# RTS591x register map
Vendor: Realtek Semiconductor Corp.; Series: RTS591x Series; File version: 1.0
CPU: ARMV8MML r0p0, little endian, MPU, FPU, VTOR, 3 interrupt priority bits, 4 SAU regions
Registers are 32-bit, read-write, reset 0x0 unless marked. A register's access mark holds for its fields unless they carry their own. Offsets are from the block's base; [hi:lo] are bit positions; {n}, {i} and the like mark numbered series; 'fields as' and 'values as' point back to an identical list.

## PUF — PUF Controller
Base 0x40010800
{0x0+4i} OTP[{i}] (i=0..255) — OTP BLOCK
{0x400+4i} PUF[{i}] (i=0..63) — PUF BLOCK
0x530 PUFZEROIZED — PUF ZEROIZATION REGISTER
{0x538+4i} OTPZEROIZED{i} (i=0..1) — OTP ZEROIZATION REGISTER
{0x570+4i} PUFLOCK{i} (i=0..3)
{0x580+4i} OTPLOCK{i} (i=0..31)
0x620 TRNGOP — TRNG OPERATION REGISTER
  [0] EN — Enable TRNG Function
    0=DISABLE (Disable TRNG function); 1=ENABLE (Enable TRNG function)
0x670 TRNGDATA — TRNG DATA OUTPUT REGISTER
0x6A0 STS — PUF STATUS REGISTER
  [0] BUSY — PUF is Busy
    0=IDLE (PUF is idle); 1=BUSY (PUF is busy)
{0x6E8+4i} OTPPOSTMSK{i} (i=0..1) — OTP POST MASK REGISTER
0x6F0 PUFPOSTMSK — PUF POST MASK REGISTER

## OTPDMA — OTP DMA Controller
Base 0x40020100
0x00 STS — STATUS REGISTER
  [0] DONE — Fetching data from OTP is finished
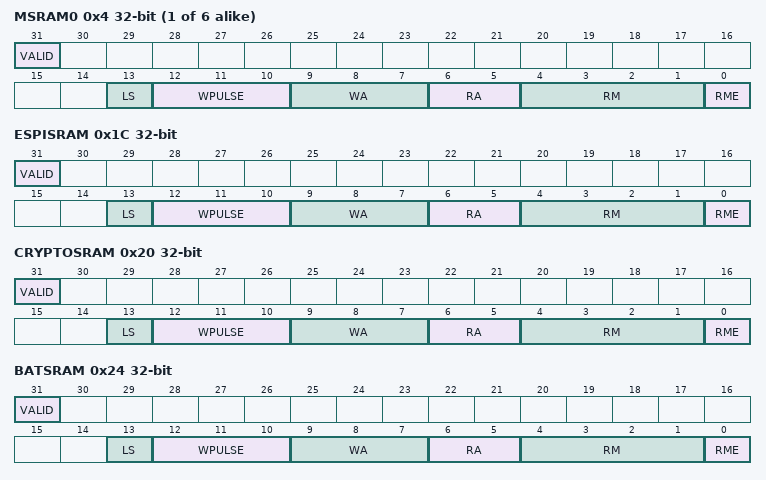
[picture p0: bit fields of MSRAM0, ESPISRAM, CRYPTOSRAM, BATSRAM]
{0x4+4i} MSRAM{i} ro (i=0..5) — MAIN SRAM #{i} CONTROL PARAMETERS
  [31] VALID — Parameters are valid or invalid
  [13] LS — Light sleep mode
  [12:10] WPULSE — Write assist pulse
  [9:7] WA — Write assist pin
  [6:5] RA — Read assist pin
  [4:1] RM — Read write margin input
  [0] RME — Read write margin enable
0x1C ESPISRAM ro — eSPI SRAM CONTROL PARAMETERS
  fields as MSRAM0
0x20 CRYPTOSRAM ro — CRYPTO SRAM CONTROL PARAMETERS
  fields as MSRAM0
0x24 BATSRAM ro — BATTERY SRAM CONTROL PARAMETERS
  fields as MSRAM0
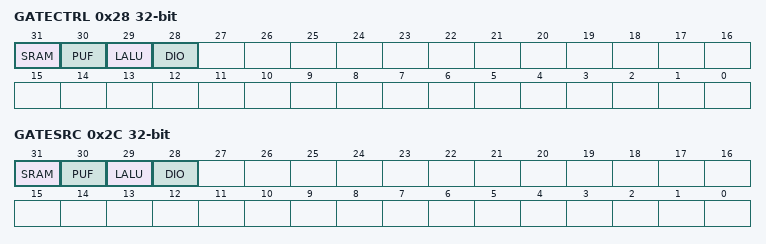
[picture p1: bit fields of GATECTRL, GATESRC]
0x28 GATECTRL ro — GATING CONTROL REGISTER
  [31] SRAM — SRAM ragne
  [30] PUF — PUF enable/disable
  [29] LALU — LALU enable/disable
  [28] DIO — DIO enable/disable
0x2C GATESRC ro — GATING SOURCE REGISTER
  [31] SRAM — SRAM ragne source
  [30] PUF — PUF enable/disable source
  [29] LALU — LALU enable/disable source
  [28] DIO — DIO enable/disable source

## PKE — Lalu Public Key Engine
Base 0x40040000
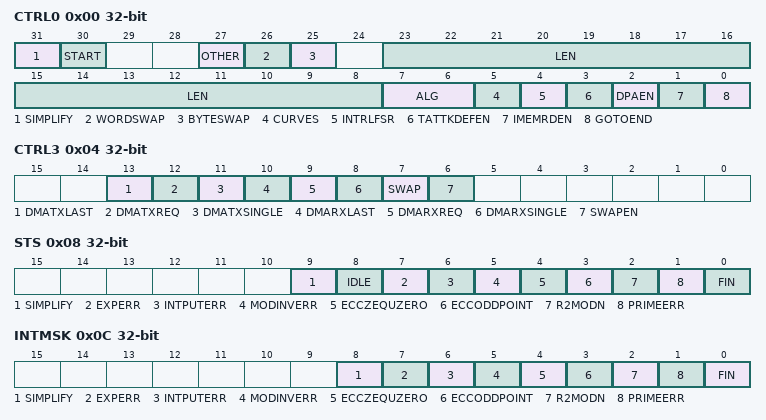
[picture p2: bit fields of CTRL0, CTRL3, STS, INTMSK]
0x00 CTRL0 — CONTROL REGISTER #0
  [31] SIMPLIFY — SIMPLIFY ECDSA/EdDSA Hash Value Ready
  [30] START — Start PKE Function
  [27] OTHER — Other Function Enable
  [26] WORDSWAP — Enable Word Swap
  [25] BYTESWAP — Enable Bytes Swap
  [23:8] LEN — Precise RSA/ECC Length in Bits
  [7:6] ALG — Algirom Selection
    0=ECC_PRIME (Use ECC prime field); 1=ECC_BINARY (Use ECC binary field); 2=RSA (Use RSA); 3=EDWARD_MONTGOMERY (Use Edwards or Montgomery curves)
  [5] CURVES
    0=EDWARD (Use Edward curves); 1=MONTGOMERY (Use Montgomery curves)
  [4] INTRLFSR — Use Internal LFSR
  [3] TATTKDEFEN — Timing Attack Defense Enable
  [2] DPAEN — DPA Defense Enable
  [1] IMEMRDEN — Enable IMEM Read
  [0] GOTOEND — Go To End Loop
0x04 CTRL3 — CONTROL REGISTER #3
  [13] DMATXLAST
  [12] DMATXREQ
  [11] DMATXSINGLE
  [10] DMARXLAST
  [9] DMARXREQ
  [8] DMARXSINGLE
  [7] SWAP — Coorinate Swap or Not
  [6] SWAPEN — Coorinate Swap Enable
0x08 STS — STATUS REGISTER
  [9] SIMPLIFY — SIMPLIFY_ECDSA/EdDSA need hash value
  [8] IDLE — PKE Idle
  [7] EXPERR — No Valid Exponent
  [6] INTPUTERR — N Less Input Message For RSA
  [5] MODINVERR — Modulat Inverse Fail
  [4] ECCZEQUZERO — ECC Z = 0
  [3] ECCODDPOINT
  [2] R2MODN — R^2 Mod N Fail
  [1] PRIMEERR — Prime Check Error
  [0] FIN — ECC/RSA Operation Finish
0x0C INTMSK — INTERRUPT MASK REGISTER
  [8] SIMPLIFY — Masked SIMPLIFY Interrupt
  [7] EXPERR — Masked EXPERR Interrupt
  [6] INTPUTERR — Masked INTPUTERR Interrupt
  [5] MODINVERR — Masked MODINVERR Interrupt
  [4] ECCZEQUZERO — Masked ECCZEQUZERO Interrupt
  [3] ECCODDPOINT — Masked ECCODDPOINT Interrupt
  [2] R2MODN — Masked R2MODN Interrupt
  [1] PRIMEERR — Masked PRIMEERR Interrupt
  [0] FIN — Masked FIN Interrupt
0x10 CTRL2 — CONTROL REGISTER #2
0x14 SWAPADDR — SWAP ADDRESS REGISTER
  [11:5] ADDR — Word Swap Base Address in Word
0x1C VERSION — VERSION NUMBER REGISTER
0x10000 MMEM — PKE MAIN MEMORY
0x20000 TMEM — PKE TEMPORARY MEMORY
0x30000 IROM — PKE INSTRUCTION MEMORY
